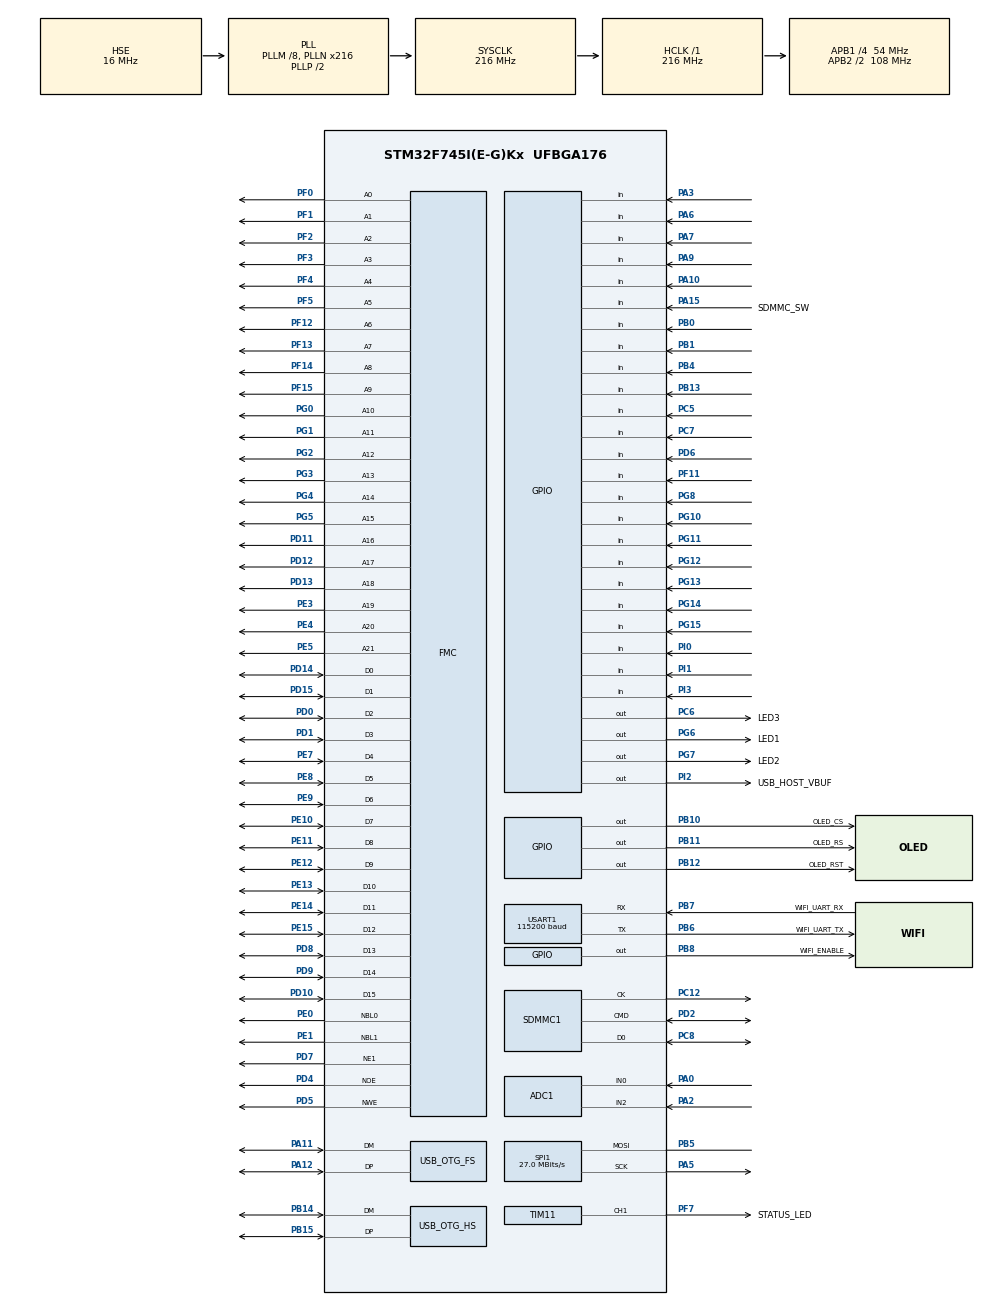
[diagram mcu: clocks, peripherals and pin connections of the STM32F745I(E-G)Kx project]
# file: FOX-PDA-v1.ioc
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ADC1.Channel-0\#ChannelRegularConversion=ADC_CHANNEL_0
ADC1.Channel-1\#ChannelRegularConversion=ADC_CHANNEL_2
ADC1.ClockPrescaler=ADC_CLOCK_SYNC_PCLK_DIV8
ADC1.ContinuousConvMode=ENABLE
ADC1.DMAContinuousRequests=ENABLE
ADC1.NbrOfConversion=2
ADC1.NbrOfConversionFlag=1
ADC1.Rank-0\#ChannelRegularConversion=1
ADC1.Rank-1\#ChannelRegularConversion=2
ADC1.SamplingTime-0\#ChannelRegularConversion=ADC_SAMPLETIME_144CYCLES
ADC1.SamplingTime-1\#ChannelRegularConversion=ADC_SAMPLETIME_144CYCLES
ADC1.master=1
Dma.ADC1.0.Direction=DMA_PERIPH_TO_MEMORY
Dma.ADC1.0.FIFOMode=DMA_FIFOMODE_DISABLE
Dma.ADC1.0.Instance=DMA2_Stream0
Dma.ADC1.0.MemDataAlignment=DMA_MDATAALIGN_WORD
Dma.ADC1.0.MemInc=DMA_MINC_ENABLE
Dma.ADC1.0.Mode=DMA_CIRCULAR
Dma.ADC1.0.PeriphDataAlignment=DMA_PDATAALIGN_WORD
Dma.ADC1.0.PeriphInc=DMA_PINC_DISABLE
Dma.ADC1.0.Priority=DMA_PRIORITY_LOW
Dma.Request0=ADC1
Dma.Request1=SDMMC1_RX
Dma.Request2=SDMMC1_TX
Dma.Request3=SPI1_TX
Dma.SDMMC1_RX.1.Direction=DMA_PERIPH_TO_MEMORY
Dma.SDMMC1_RX.1.FIFOMode=DMA_FIFOMODE_ENABLE
Dma.SDMMC1_RX.1.FIFOThreshold=DMA_FIFO_THRESHOLD_FULL
Dma.SDMMC1_RX.1.Instance=DMA2_Stream3
Dma.SDMMC1_RX.1.MemBurst=DMA_MBURST_INC4
Dma.SDMMC1_RX.1.MemDataAlignment=DMA_MDATAALIGN_WORD
Dma.SDMMC1_RX.1.MemInc=DMA_MINC_ENABLE
Dma.SDMMC1_RX.1.Mode=DMA_PFCTRL
Dma.SDMMC1_RX.1.PeriphBurst=DMA_PBURST_INC4
Dma.SDMMC1_RX.1.PeriphDataAlignment=DMA_PDATAALIGN_WORD
Dma.SDMMC1_RX.1.PeriphInc=DMA_PINC_DISABLE
Dma.SDMMC1_RX.1.Priority=DMA_PRIORITY_LOW
Dma.SDMMC1_TX.2.Direction=DMA_MEMORY_TO_PERIPH
Dma.SDMMC1_TX.2.FIFOMode=DMA_FIFOMODE_ENABLE
Dma.SDMMC1_TX.2.FIFOThreshold=DMA_FIFO_THRESHOLD_FULL
Dma.SDMMC1_TX.2.Instance=DMA2_Stream6
Dma.SDMMC1_TX.2.MemBurst=DMA_MBURST_INC4
Dma.SDMMC1_TX.2.MemDataAlignment=DMA_MDATAALIGN_WORD
Dma.SDMMC1_TX.2.MemInc=DMA_MINC_ENABLE
Dma.SDMMC1_TX.2.Mode=DMA_PFCTRL
Dma.SDMMC1_TX.2.PeriphBurst=DMA_PBURST_INC4
Dma.SDMMC1_TX.2.PeriphDataAlignment=DMA_PDATAALIGN_WORD
Dma.SDMMC1_TX.2.PeriphInc=DMA_PINC_DISABLE
Dma.SDMMC1_TX.2.Priority=DMA_PRIORITY_LOW
Dma.SPI1_TX.3.Direction=DMA_MEMORY_TO_PERIPH
Dma.SPI1_TX.3.FIFOMode=DMA_FIFOMODE_DISABLE
Dma.SPI1_TX.3.Instance=DMA2_Stream5
Dma.SPI1_TX.3.MemDataAlignment=DMA_MDATAALIGN_BYTE
Dma.SPI1_TX.3.MemInc=DMA_MINC_DISABLE
Dma.SPI1_TX.3.Mode=DMA_NORMAL
Dma.SPI1_TX.3.PeriphDataAlignment=DMA_PDATAALIGN_BYTE
Dma.SPI1_TX.3.PeriphInc=DMA_PINC_DISABLE
Dma.SPI1_TX.3.Priority=DMA_PRIORITY_VERY_HIGH
FATFS.BSP.number=1
FATFS.USE_DMA_CODE_SD=0
FATFS._FS_NOFSINFO=0
FATFS._MAX_SS=4096
FATFS._MIN_SS=512
FATFS._MULTI_PARTITION=0
FATFS._USE_LFN=1
FATFS0.BSP.STBoard=false
FATFS0.BSP.api=Unknown
FATFS0.BSP.instance=PA15
FATFS0.BSP.ip=GPIO
FATFS0.BSP.mode=Input
FATFS0.BSP.name=Detect_SDIO
FATFS0.BSP.solution=PA15
FMC.AddressSetupTime1=5
FMC.BusTurnAroundDuration1=1
FMC.DataSetupTime1=8
FMC.WriteOperation1=FMC_WRITE_OPERATION_ENABLE
Mcu.Family=STM32F7
Mcu.Name=STM32F745I(E-G)Kx
Mcu.Package=UFBGA176
NVIC.DMA2_Stream0_IRQn=true\:0\:0\:false\:false\:true\:false\:true\:true
NVIC.DMA2_Stream3_IRQn=true\:0\:0\:false\:false\:true\:false\:true\:true
NVIC.DMA2_Stream5_IRQn=true\:0\:0\:false\:false\:true\:false\:true\:true
NVIC.DMA2_Stream6_IRQn=true\:0\:0\:false\:false\:true\:false\:true\:true
NVIC.OTG_FS_IRQn=true\:0\:0\:false\:false\:true\:false\:true\:true
NVIC.OTG_HS_IRQn=true\:0\:0\:false\:false\:true\:false\:true\:true
NVIC.PriorityGroup=NVIC_PRIORITYGROUP_4
NVIC.SPI1_IRQn=true\:0\:0\:false\:false\:true\:true\:true\:true
PA0/WKUP.Signal=ADCx_IN0
PA10.Signal=GPIO_Input
PA11.Mode=Host_Only
PA11.Signal=USB_OTG_FS_DM
PA12.Mode=Host_Only
PA12.Signal=USB_OTG_FS_DP
PA13.Mode=Trace_Asynchronous_SW
PA13.Signal=SYS_JTMS-SWDIO
PA14.Mode=Trace_Asynchronous_SW
PA14.Signal=SYS_JTCK-SWCLK
PA15.GPIO_Label=SDMMC_SW
PA15.Signal=GPIO_Input
PA2.Signal=ADCx_IN2
PA3.Signal=GPIO_Input
PA5.GPIO_Speed=GPIO_SPEED_FREQ_HIGH
PA5.Mode=Simplex_Bidirectional_Master
PA5.Signal=SPI1_SCK
PA6.Signal=GPIO_Input
PA7.Signal=GPIO_Input
PA9.Signal=GPIO_Input
PB0.Signal=GPIO_Input
PB1.Signal=GPIO_Input
PB10.GPIO_Label=OLED_CS
PB10.GPIO_Speed=GPIO_SPEED_FREQ_MEDIUM
PB10.PinState=GPIO_PIN_RESET
PB10.Signal=GPIO_Output
PB11.GPIO_Label=OLED_RS
PB11.GPIO_Speed=GPIO_SPEED_FREQ_MEDIUM
PB11.PinState=GPIO_PIN_RESET
PB11.Signal=GPIO_Output
PB12.GPIO_Label=OLED_RST
PB12.GPIO_Speed=GPIO_SPEED_FREQ_MEDIUM
PB12.PinState=GPIO_PIN_RESET
PB12.Signal=GPIO_Output
PB13.Signal=GPIO_Input
PB14.Mode=Device_Only_FS
PB14.Signal=USB_OTG_HS_DM
PB15.Mode=Device_Only_FS
PB15.Signal=USB_OTG_HS_DP
PB3.Mode=Trace_Asynchronous_SW
PB3.Signal=SYS_JTDO-SWO
PB4.Signal=GPIO_Input
PB5.GPIO_Speed=GPIO_SPEED_FREQ_HIGH
PB5.Mode=Simplex_Bidirectional_Master
PB5.Signal=SPI1_MOSI
PB6.GPIO_Label=WIFI_UART_TX
PB6.Mode=Asynchronous
PB6.Signal=USART1_TX
PB7.GPIO_Label=WIFI_UART_RX
PB7.Mode=Asynchronous
PB7.Signal=USART1_RX
PB8.GPIO_Label=WIFI_ENABLE
PB8.Signal=GPIO_Output
PC10.Signal=SDMMC1_D2
PC11.Signal=SDMMC1_D3
PC12.Mode=SD_1_bit
PC12.Signal=SDMMC1_CK
PC14/OSC32_IN.Mode=LSE-External-Oscillator
PC14/OSC32_IN.Signal=RCC_OSC32_IN
PC15/OSC32_OUT.Mode=LSE-External-Oscillator
PC15/OSC32_OUT.Signal=RCC_OSC32_OUT
PC5.Signal=GPIO_Input
PC6.GPIO_Label=LED3
PC6.Signal=GPIO_Output
PC7.Signal=GPIO_Input
PC8.Mode=SD_1_bit
PC8.Signal=SDMMC1_D0
PC9.Signal=SDMMC1_D1
PD0.Signal=FMC_D2_DA2
PD1.Signal=FMC_D3_DA3
PD10.Signal=FMC_D15_DA15
PD11.Signal=FMC_A16_CLE
PD12.Signal=FMC_A17_ALE
PD13.Signal=FMC_A18
PD14.Signal=FMC_D0_DA0
PD15.Signal=FMC_D1_DA1
PD2.Mode=SD_1_bit
PD2.Signal=SDMMC1_CMD
PD4.Signal=FMC_NOE
PD5.Signal=FMC_NWE
PD6.Signal=GPIO_Input
PD7.Mode=NorPsramChipSelect1_1
PD7.Signal=FMC_NE1
PD8.Signal=FMC_D13_DA13
PD9.Signal=FMC_D14_DA14
PE0.Signal=FMC_NBL0
PE1.Signal=FMC_NBL1
PE10.Signal=FMC_D7_DA7
PE11.Signal=FMC_D8_DA8
PE12.Signal=FMC_D9_DA9
PE13.Signal=FMC_D10_DA10
PE14.Signal=FMC_D11_DA11
PE15.Signal=FMC_D12_DA12
PE3.Signal=FMC_A19
PE4.Signal=FMC_A20
PE5.Signal=FMC_A21
PE7.Signal=FMC_D4_DA4
PE8.Signal=FMC_D5_DA5
PE9.Signal=FMC_D6_DA6
PF0.Signal=FMC_A0
PF1.Signal=FMC_A1
PF11.Signal=GPIO_Input
PF12.Signal=FMC_A6
PF13.Signal=FMC_A7
PF14.Signal=FMC_A8
PF15.Signal=FMC_A9
PF2.Signal=FMC_A2
PF3.Signal=FMC_A3
PF4.Signal=FMC_A4
PF5.Signal=FMC_A5
PF7.GPIO_Label=STATUS_LED
PF7.Signal=S_TIM11_CH1
PG0.Signal=FMC_A10
PG1.Signal=FMC_A11
PG10.Signal=GPIO_Input
PG11.Signal=GPIO_Input
PG12.Signal=GPIO_Input
PG13.Signal=GPIO_Input
PG14.Signal=GPIO_Input
PG15.Signal=GPIO_Input
PG2.Signal=FMC_A12
PG3.Signal=FMC_A13
PG4.Signal=FMC_A14_BA0
PG5.Signal=FMC_A15_BA1
PG6.GPIO_Label=LED1
PG6.Signal=GPIO_Output
PG7.GPIO_Label=LED2
PG7.Signal=GPIO_Output
PG8.Signal=GPIO_Input
PH0/OSC_IN.Mode=HSE-External-Oscillator
PH0/OSC_IN.Signal=RCC_OSC_IN
PH1/OSC_OUT.Mode=HSE-External-Oscillator
PH1/OSC_OUT.Signal=RCC_OSC_OUT
PI0.Signal=GPIO_Input
PI1.Signal=GPIO_Input
PI2.GPIO_Label=USB_HOST_VBUF
PI2.Signal=GPIO_Output
PI3.Signal=GPIO_Input
ProjectManager.HeapSize=0x200
ProjectManager.StackSize=0x400
ProjectManager.TargetToolchain=STM32CubeIDE
RCC.AHBFreq_Value=216000000
RCC.APB1CLKDivider=RCC_HCLK_DIV4
RCC.APB1Freq_Value=54000000
RCC.APB1TimFreq_Value=108000000
RCC.APB2CLKDivider=RCC_HCLK_DIV2
RCC.APB2Freq_Value=108000000
RCC.APB2TimFreq_Value=216000000
RCC.CortexFreq_Value=216000000
RCC.HCLKFreq_Value=216000000
RCC.HSE_VALUE=16000000
RCC.HSI_VALUE=16000000
RCC.PLLI2SN=181
RCC.PLLM=8
RCC.PLLN=216
RCC.PLLQ=9
RCC.PLLSAIN=50
RCC.SDMMCClockSelection=RCC_SDMMC1CLKSOURCE_CLK48
RCC.SYSCLKFreq_VALUE=216000000
RCC.SYSCLKSource=RCC_SYSCLKSOURCE_PLLCLK
RCC.USBFreq_Value=48000000
RCC.VCOOutputFreq_Value=432000000
SDMMC1.ClockBypass=SDMMC_CLOCK_BYPASS_DISABLE
SDMMC1.ClockDiv=4
SDMMC1.HardwareFlowControl=SDMMC_HARDWARE_FLOW_CONTROL_ENABLE
SH.ADCx_IN0.0=ADC1_IN0,IN0
SH.ADCx_IN2.0=ADC1_IN2,IN2
SH.FMC_A0.0=FMC_A0,22b-a1
SH.FMC_A1.0=FMC_A1,22b-a1
SH.FMC_A10.0=FMC_A10,22b-a1
SH.FMC_A11.0=FMC_A11,22b-a1
SH.FMC_A12.0=FMC_A12,22b-a1
SH.FMC_A13.0=FMC_A13,22b-a1
SH.FMC_A14_BA0.0=FMC_A14,22b-a1
SH.FMC_A15_BA1.0=FMC_A15,22b-a1
SH.FMC_A16_CLE.0=FMC_A16,22b-a1
SH.FMC_A17_ALE.0=FMC_A17,22b-a1
SH.FMC_A18.0=FMC_A18,22b-a1
SH.FMC_A19.0=FMC_A19,22b-a1
SH.FMC_A2.0=FMC_A2,22b-a1
SH.FMC_A20.0=FMC_A20,22b-a1
SH.FMC_A21.0=FMC_A21,22b-a1
SH.FMC_A3.0=FMC_A3,22b-a1
SH.FMC_A4.0=FMC_A4,22b-a1
SH.FMC_A5.0=FMC_A5,22b-a1
SH.FMC_A6.0=FMC_A6,22b-a1
SH.FMC_A7.0=FMC_A7,22b-a1
SH.FMC_A8.0=FMC_A8,22b-a1
SH.FMC_A9.0=FMC_A9,22b-a1
SH.FMC_D0_DA0.0=FMC_D0,16b-d1
SH.FMC_D10_DA10.0=FMC_D10,16b-d1
SH.FMC_D11_DA11.0=FMC_D11,16b-d1
SH.FMC_D12_DA12.0=FMC_D12,16b-d1
SH.FMC_D13_DA13.0=FMC_D13,16b-d1
SH.FMC_D14_DA14.0=FMC_D14,16b-d1
SH.FMC_D15_DA15.0=FMC_D15,16b-d1
SH.FMC_D1_DA1.0=FMC_D1,16b-d1
SH.FMC_D2_DA2.0=FMC_D2,16b-d1
SH.FMC_D3_DA3.0=FMC_D3,16b-d1
SH.FMC_D4_DA4.0=FMC_D4,16b-d1
SH.FMC_D5_DA5.0=FMC_D5,16b-d1
SH.FMC_D6_DA6.0=FMC_D6,16b-d1
SH.FMC_D7_DA7.0=FMC_D7,16b-d1
SH.FMC_D8_DA8.0=FMC_D8,16b-d1
SH.FMC_D9_DA9.0=FMC_D9,16b-d1
SH.FMC_NBL0.0=FMC_NBL0,2ByteEnable1
SH.FMC_NBL1.0=FMC_NBL1,2ByteEnable1
SH.FMC_NOE.0=FMC_NOE,Psram1
SH.FMC_NWE.0=FMC_NWE,Psram1
SH.S_TIM11_CH1.0=TIM11_CH1,PWM Generation1 CH1
SPI1.BaudRatePrescaler=SPI_BAUDRATEPRESCALER_4
SPI1.CalculateBaudRate=27.0 MBits/s
SPI1.DataSize=SPI_DATASIZE_8BIT
SPI1.Direction=SPI_DIRECTION_1LINE
SPI1.Mode=SPI_MODE_MASTER
SPI1.VirtualType=VM_MASTER
TIM11.Channel=TIM_CHANNEL_1
USART1.BaudRate=115200
USART1.VirtualMode-Asynchronous=VM_ASYNC
USART1.WordLength=WORDLENGTH_8B
USB_DEVICE.CLASS_NAME_HS=CDC
USB_DEVICE.VirtualMode-CDC_HS=Cdc
USB_DEVICE.VirtualModeHS=Cdc_HS
USB_HOST.BSP.number=1
USB_HOST.USBH_HandleTypeDef-CDC_FS=hUsbHostFS
USB_HOST.VirtualModeFS=Cdc
USB_HOST0.BSP.STBoard=false
USB_HOST0.BSP.api=Unknown
USB_HOST0.BSP.instance=PI2
USB_HOST0.BSP.ip=GPIO
USB_HOST0.BSP.mode=Output
USB_HOST0.BSP.name=Drive_VBUS_FS
USB_HOST0.BSP.solution=PI2
USB_OTG_FS.VirtualMode=Host_Only
USB_OTG_FS.phy_itface=HCD_PHY_EMBEDDED
USB_OTG_HS.VirtualMode-Device_Only_FS=Device_Only_FS
VP_FATFS_VS_SDIO.Mode=SDIO
VP_TIM11_VS_ClockSourceINT.Mode=Enable_Timer
VP_TIM1_VS_ClockSourceINT.Mode=Internal
VP_USB_DEVICE_VS_USB_DEVICE_CDC_HS.Mode=CDC_HS
VP_USB_HOST_VS_USB_HOST_CDC_FS.Mode=CDC_FS
board=custom

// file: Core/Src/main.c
/* USER CODE BEGIN Header */
/**
 ******************************************************************************
 * @file           : main.c
 * @brief          : Main program body
 ******************************************************************************
 * @attention
 *
 * Copyright (c) 2023 STMicroelectronics.
 * All rights reserved.
 *
 * This software is licensed under terms that can be found in the LICENSE file
 * in the root directory of this software component.
 * If no LICENSE file comes with this software, it is provided AS-IS.
 *
 ******************************************************************************
 */
/* USER CODE END Header */
#include "main.h"
#include "fatfs.h"
#include "usb_device.h"
#include "usb_host.h"

/* USER CODE BEGIN Includes */
#include "usbd_cdc_if.h"
#include "string.h"
#include "stm32f7xx_ll_fmc.h"
#include "math.h"

#include "Ffunctions/f_debug.h"
#include "System/System.h"

#include "Drivers/MDT0096AIH.h"
/* USER CODE END Includes */

ADC_HandleTypeDef hadc1;
DMA_HandleTypeDef hdma_adc1;

SD_HandleTypeDef hsd1;
DMA_HandleTypeDef hdma_sdmmc1_rx;
DMA_HandleTypeDef hdma_sdmmc1_tx;

SPI_HandleTypeDef hspi1;
DMA_HandleTypeDef hdma_spi1_tx;

TIM_HandleTypeDef htim1;
TIM_HandleTypeDef htim11;

UART_HandleTypeDef huart1;

SRAM_HandleTypeDef hsram1;

/* USER CODE BEGIN PV */

// system state management
System_t system_state;

MDT0096AIH_t oled;

/* USER CODE END PV */

void SystemClock_Config(void);
static void MX_GPIO_Init(void);
static void MX_DMA_Init(void);
static void MX_SDMMC1_SD_Init(void);
static void MX_USART1_UART_Init(void);
static void MX_TIM1_Init(void);
static void MX_TIM11_Init(void);
static void MX_ADC1_Init(void);
static void MX_FMC_Init(void);
static void MX_SPI1_Init(void);
void MX_USB_HOST_Process(void);

/* USER CODE BEGIN 0 */
uint8_t adc_ready = 0;
uint32_t adc_buffer[2];
uint32_t adc_dma_buffer[2];
void HAL_ADC_ConvCpltCallback(ADC_HandleTypeDef *AdcHandle)
{
	adc_ready = 1;
	memcpy(adc_buffer, adc_dma_buffer, 2 * sizeof(uint32_t));
}

/* USER CODE END 0 */

int main(void)
{

	/* MCU Configuration--------------------------------------------------------*/

	/* Reset of all peripherals, Initializes the Flash interface and the Systick. */
	HAL_Init();

	/* Configure the system clock */
	SystemClock_Config();

	/* Initialize all configured peripherals */
	MX_GPIO_Init();
	MX_DMA_Init();
	MX_SDMMC1_SD_Init();
	MX_FATFS_Init();
	MX_USB_DEVICE_Init();
	MX_USB_HOST_Init();
	MX_USART1_UART_Init();
	MX_TIM1_Init();
	MX_TIM11_Init();
	MX_ADC1_Init();
	MX_FMC_Init();
	MX_SPI1_Init();
	/* USER CODE BEGIN 2 */

	//	// system startup
	//	System_init(&system_state);
	//
	//	// system init terminal log
	//	System_initLog(&system_state);
	//	System_selfTestLog(&system_state);

	HAL_Delay(1000);

	// init display
	MDT0096AIH_Init(&oled, &hspi1,
			OLED_RS_GPIO_Port, OLED_RS_Pin,
			OLED_RST_GPIO_Port, OLED_RST_Pin,
			OLED_CS_GPIO_Port, OLED_CS_Pin);

	uint8_t frame_buffer[38400];// = (uint8_t*)SRAM_ADDRESS;
	uint8_t brightness = 0x00;
	/* USER CODE END 2 */

	/* Infinite loop */
	/* USER CODE BEGIN WHILE */
	while (1)
	{
		brightness += 1;
		memset(frame_buffer, brightness, 38400);
		HAL_SPI_Transmit_DMA(&hspi1, frame_buffer, 38400);
		HAL_Delay(16);
		/* USER CODE END WHILE */
		MX_USB_HOST_Process();
	}
}

void SystemClock_Config(void)
{
	RCC_OscInitTypeDef RCC_OscInitStruct = {0};
	RCC_ClkInitTypeDef RCC_ClkInitStruct = {0};

	/** Configure LSE Drive Capability
	 */
	HAL_PWR_EnableBkUpAccess();

	/** Configure the main internal regulator output voltage
	 */
	__HAL_RCC_PWR_CLK_ENABLE();
	__HAL_PWR_VOLTAGESCALING_CONFIG(PWR_REGULATOR_VOLTAGE_SCALE1);

	/** Initializes the RCC Oscillators according to the specified parameters
	 * in the RCC_OscInitTypeDef structure.
	 */
	RCC_OscInitStruct.OscillatorType = RCC_OSCILLATORTYPE_HSE;
	RCC_OscInitStruct.HSEState = RCC_HSE_ON;
	RCC_OscInitStruct.PLL.PLLState = RCC_PLL_ON;
	RCC_OscInitStruct.PLL.PLLSource = RCC_PLLSOURCE_HSE;
	RCC_OscInitStruct.PLL.PLLM = 8;
	RCC_OscInitStruct.PLL.PLLN = 216;
	RCC_OscInitStruct.PLL.PLLP = RCC_PLLP_DIV2;
	RCC_OscInitStruct.PLL.PLLQ = 9;
	if (HAL_RCC_OscConfig(&RCC_OscInitStruct) != HAL_OK)
	{
		Error_Handler();
	}

	/** Activate the Over-Drive mode
	 */
	if (HAL_PWREx_EnableOverDrive() != HAL_OK)
	{
		Error_Handler();
	}

	/** Initializes the CPU, AHB and APB buses clocks
	 */
	RCC_ClkInitStruct.ClockType = RCC_CLOCKTYPE_HCLK|RCC_CLOCKTYPE_SYSCLK
			|RCC_CLOCKTYPE_PCLK1|RCC_CLOCKTYPE_PCLK2;
	RCC_ClkInitStruct.SYSCLKSource = RCC_SYSCLKSOURCE_PLLCLK;
	RCC_ClkInitStruct.AHBCLKDivider = RCC_SYSCLK_DIV1;
	RCC_ClkInitStruct.APB1CLKDivider = RCC_HCLK_DIV4;
	RCC_ClkInitStruct.APB2CLKDivider = RCC_HCLK_DIV2;

	if (HAL_RCC_ClockConfig(&RCC_ClkInitStruct, FLASH_LATENCY_7) != HAL_OK)
	{
		Error_Handler();
	}
}

static void MX_ADC1_Init(void)
{

	ADC_ChannelConfTypeDef sConfig = {0};

	/** Configure the global features of the ADC (Clock, Resolution, Data Alignment and number of conversion)
	 */
	hadc1.Instance = ADC1;
	hadc1.Init.ClockPrescaler = ADC_CLOCK_SYNC_PCLK_DIV8;
	hadc1.Init.Resolution = ADC_RESOLUTION_12B;
	hadc1.Init.ScanConvMode = ADC_SCAN_ENABLE;
	hadc1.Init.ContinuousConvMode = ENABLE;
	hadc1.Init.DiscontinuousConvMode = DISABLE;
	hadc1.Init.ExternalTrigConvEdge = ADC_EXTERNALTRIGCONVEDGE_NONE;
	hadc1.Init.ExternalTrigConv = ADC_SOFTWARE_START;
	hadc1.Init.DataAlign = ADC_DATAALIGN_RIGHT;
	hadc1.Init.NbrOfConversion = 2;
	hadc1.Init.DMAContinuousRequests = ENABLE;
	hadc1.Init.EOCSelection = ADC_EOC_SINGLE_CONV;
	if (HAL_ADC_Init(&hadc1) != HAL_OK)
	{
		Error_Handler();
	}

	/** Configure for the selected ADC regular channel its corresponding rank in the sequencer and its sample time.
	 */
	sConfig.Channel = ADC_CHANNEL_0;
	sConfig.Rank = ADC_REGULAR_RANK_1;
	sConfig.SamplingTime = ADC_SAMPLETIME_144CYCLES;
	if (HAL_ADC_ConfigChannel(&hadc1, &sConfig) != HAL_OK)
	{
		Error_Handler();
	}

	/** Configure for the selected ADC regular channel its corresponding rank in the sequencer and its sample time.
	 */
	sConfig.Channel = ADC_CHANNEL_2;
	sConfig.Rank = ADC_REGULAR_RANK_2;
	if (HAL_ADC_ConfigChannel(&hadc1, &sConfig) != HAL_OK)
	{
		Error_Handler();
	}

}

static void MX_SDMMC1_SD_Init(void)
{

	hsd1.Instance = SDMMC1;
	hsd1.Init.ClockEdge = SDMMC_CLOCK_EDGE_RISING;
	hsd1.Init.ClockBypass = SDMMC_CLOCK_BYPASS_DISABLE;
	hsd1.Init.ClockPowerSave = SDMMC_CLOCK_POWER_SAVE_DISABLE;
	hsd1.Init.BusWide = SDMMC_BUS_WIDE_1B;
	hsd1.Init.HardwareFlowControl = SDMMC_HARDWARE_FLOW_CONTROL_ENABLE;
	hsd1.Init.ClockDiv = 4;
	/* USER CODE BEGIN SDMMC1_Init 2 */
	HAL_SD_Init(&hsd1);
	/* USER CODE END SDMMC1_Init 2 */

}

static void MX_SPI1_Init(void)
{

	/* SPI1 parameter configuration*/
	hspi1.Instance = SPI1;
	hspi1.Init.Mode = SPI_MODE_MASTER;
	hspi1.Init.Direction = SPI_DIRECTION_1LINE;
	hspi1.Init.DataSize = SPI_DATASIZE_8BIT;
	hspi1.Init.CLKPolarity = SPI_POLARITY_LOW;
	hspi1.Init.CLKPhase = SPI_PHASE_1EDGE;
	hspi1.Init.NSS = SPI_NSS_SOFT;
	hspi1.Init.BaudRatePrescaler = SPI_BAUDRATEPRESCALER_4;
	hspi1.Init.FirstBit = SPI_FIRSTBIT_MSB;
	hspi1.Init.TIMode = SPI_TIMODE_DISABLE;
	hspi1.Init.CRCCalculation = SPI_CRCCALCULATION_DISABLE;
	hspi1.Init.CRCPolynomial = 7;
	hspi1.Init.CRCLength = SPI_CRC_LENGTH_DATASIZE;
	hspi1.Init.NSSPMode = SPI_NSS_PULSE_ENABLE;
	if (HAL_SPI_Init(&hspi1) != HAL_OK)
	{
		Error_Handler();
	}

}

static void MX_TIM1_Init(void)
{

	TIM_ClockConfigTypeDef sClockSourceConfig = {0};
	TIM_MasterConfigTypeDef sMasterConfig = {0};

	htim1.Instance = TIM1;
	htim1.Init.Prescaler = 0;
	htim1.Init.CounterMode = TIM_COUNTERMODE_UP;
	htim1.Init.Period = 65535;
	htim1.Init.ClockDivision = TIM_CLOCKDIVISION_DIV1;
	htim1.Init.RepetitionCounter = 0;
	htim1.Init.AutoReloadPreload = TIM_AUTORELOAD_PRELOAD_DISABLE;
	if (HAL_TIM_Base_Init(&htim1) != HAL_OK)
	{
		Error_Handler();
	}
	sClockSourceConfig.ClockSource = TIM_CLOCKSOURCE_INTERNAL;
	if (HAL_TIM_ConfigClockSource(&htim1, &sClockSourceConfig) != HAL_OK)
	{
		Error_Handler();
	}
	sMasterConfig.MasterOutputTrigger = TIM_TRGO_RESET;
	sMasterConfig.MasterOutputTrigger2 = TIM_TRGO2_RESET;
	sMasterConfig.MasterSlaveMode = TIM_MASTERSLAVEMODE_DISABLE;
	if (HAL_TIMEx_MasterConfigSynchronization(&htim1, &sMasterConfig) != HAL_OK)
	{
		Error_Handler();
	}

}

static void MX_TIM11_Init(void)
{

	TIM_OC_InitTypeDef sConfigOC = {0};

	htim11.Instance = TIM11;
	htim11.Init.Prescaler = 0;
	htim11.Init.CounterMode = TIM_COUNTERMODE_UP;
	htim11.Init.Period = 65535;
	htim11.Init.ClockDivision = TIM_CLOCKDIVISION_DIV1;
	htim11.Init.AutoReloadPreload = TIM_AUTORELOAD_PRELOAD_DISABLE;
	if (HAL_TIM_Base_Init(&htim11) != HAL_OK)
	{
		Error_Handler();
	}
	if (HAL_TIM_PWM_Init(&htim11) != HAL_OK)
	{
		Error_Handler();
	}
	sConfigOC.OCMode = TIM_OCMODE_PWM1;
	sConfigOC.Pulse = 0;
	sConfigOC.OCPolarity = TIM_OCPOLARITY_HIGH;
	sConfigOC.OCFastMode = TIM_OCFAST_DISABLE;
	if (HAL_TIM_PWM_ConfigChannel(&htim11, &sConfigOC, TIM_CHANNEL_1) != HAL_OK)
	{
		Error_Handler();
	}
	HAL_TIM_MspPostInit(&htim11);

}

static void MX_USART1_UART_Init(void)
{

	huart1.Instance = USART1;
	huart1.Init.BaudRate = 115200;
	huart1.Init.WordLength = UART_WORDLENGTH_8B;
	huart1.Init.StopBits = UART_STOPBITS_1;
	huart1.Init.Parity = UART_PARITY_NONE;
	huart1.Init.Mode = UART_MODE_TX_RX;
	huart1.Init.HwFlowCtl = UART_HWCONTROL_NONE;
	huart1.Init.OverSampling = UART_OVERSAMPLING_16;
	huart1.Init.OneBitSampling = UART_ONE_BIT_SAMPLE_DISABLE;
	huart1.AdvancedInit.AdvFeatureInit = UART_ADVFEATURE_NO_INIT;
	if (HAL_UART_Init(&huart1) != HAL_OK)
	{
		Error_Handler();
	}

}

static void MX_DMA_Init(void)
{

	/* DMA controller clock enable */
	__HAL_RCC_DMA2_CLK_ENABLE();

	/* DMA interrupt init */
	/* DMA2_Stream0_IRQn interrupt configuration */
	HAL_NVIC_SetPriority(DMA2_Stream0_IRQn, 0, 0);
	HAL_NVIC_EnableIRQ(DMA2_Stream0_IRQn);
	/* DMA2_Stream3_IRQn interrupt configuration */
	HAL_NVIC_SetPriority(DMA2_Stream3_IRQn, 0, 0);
	HAL_NVIC_EnableIRQ(DMA2_Stream3_IRQn);
	/* DMA2_Stream5_IRQn interrupt configuration */
	HAL_NVIC_SetPriority(DMA2_Stream5_IRQn, 0, 0);
	HAL_NVIC_EnableIRQ(DMA2_Stream5_IRQn);
	/* DMA2_Stream6_IRQn interrupt configuration */
	HAL_NVIC_SetPriority(DMA2_Stream6_IRQn, 0, 0);
	HAL_NVIC_EnableIRQ(DMA2_Stream6_IRQn);

}

/* FMC initialization function */
static void MX_FMC_Init(void)
{

	FMC_NORSRAM_TimingTypeDef Timing = {0};

	/** Perform the SRAM1 memory initialization sequence
	 */
	hsram1.Instance = FMC_NORSRAM_DEVICE;
	hsram1.Extended = FMC_NORSRAM_EXTENDED_DEVICE;
	/* hsram1.Init */
	hsram1.Init.NSBank = FMC_NORSRAM_BANK1;
	hsram1.Init.DataAddressMux = FMC_DATA_ADDRESS_MUX_DISABLE;
	hsram1.Init.MemoryType = FMC_MEMORY_TYPE_PSRAM;
	hsram1.Init.MemoryDataWidth = FMC_NORSRAM_MEM_BUS_WIDTH_16;
	hsram1.Init.BurstAccessMode = FMC_BURST_ACCESS_MODE_DISABLE;
	hsram1.Init.WaitSignalPolarity = FMC_WAIT_SIGNAL_POLARITY_LOW;
	hsram1.Init.WaitSignalActive = FMC_WAIT_TIMING_BEFORE_WS;
	hsram1.Init.WriteOperation = FMC_WRITE_OPERATION_ENABLE;
	hsram1.Init.WaitSignal = FMC_WAIT_SIGNAL_DISABLE;
	hsram1.Init.ExtendedMode = FMC_EXTENDED_MODE_DISABLE;
	hsram1.Init.AsynchronousWait = FMC_ASYNCHRONOUS_WAIT_DISABLE;
	hsram1.Init.WriteBurst = FMC_WRITE_BURST_DISABLE;
	hsram1.Init.ContinuousClock = FMC_CONTINUOUS_CLOCK_SYNC_ONLY;
	hsram1.Init.WriteFifo = FMC_WRITE_FIFO_ENABLE;
	hsram1.Init.PageSize = FMC_PAGE_SIZE_NONE;
	/* Timing */
	Timing.AddressSetupTime = 5;
	Timing.AddressHoldTime = 15;
	Timing.DataSetupTime = 8;
	Timing.BusTurnAroundDuration = 1;
	Timing.CLKDivision = 16;
	Timing.DataLatency = 17;
	Timing.AccessMode = FMC_ACCESS_MODE_A;
	/* ExtTiming */

	if (HAL_SRAM_Init(&hsram1, &Timing, NULL) != HAL_OK)
	{
		Error_Handler( );
	}

}

static void MX_GPIO_Init(void)
{
	GPIO_InitTypeDef GPIO_InitStruct = {0};

	/* GPIO Ports Clock Enable */
	__HAL_RCC_GPIOE_CLK_ENABLE();
	__HAL_RCC_GPIOB_CLK_ENABLE();
	__HAL_RCC_GPIOG_CLK_ENABLE();
	__HAL_RCC_GPIOD_CLK_ENABLE();
	__HAL_RCC_GPIOC_CLK_ENABLE();
	__HAL_RCC_GPIOA_CLK_ENABLE();
	__HAL_RCC_GPIOI_CLK_ENABLE();
	__HAL_RCC_GPIOF_CLK_ENABLE();
	__HAL_RCC_GPIOH_CLK_ENABLE();

	/*Configure GPIO pin Output Level */
	HAL_GPIO_WritePin(GPIOB, WIFI_ENABLE_Pin|OLED_RST_Pin|OLED_CS_Pin|OLED_RS_Pin, GPIO_PIN_RESET);

	/*Configure GPIO pin Output Level */
	HAL_GPIO_WritePin(USB_HOST_VBUF_GPIO_Port, USB_HOST_VBUF_Pin, GPIO_PIN_RESET);

	/*Configure GPIO pin Output Level */
	HAL_GPIO_WritePin(LED3_GPIO_Port, LED3_Pin, GPIO_PIN_RESET);

	/*Configure GPIO pin Output Level */
	HAL_GPIO_WritePin(GPIOG, LED2_Pin|LED1_Pin, GPIO_PIN_RESET);

	/*Configure GPIO pin : WIFI_ENABLE_Pin */
	GPIO_InitStruct.Pin = WIFI_ENABLE_Pin;
	GPIO_InitStruct.Mode = GPIO_MODE_OUTPUT_PP;
	GPIO_InitStruct.Pull = GPIO_NOPULL;
	GPIO_InitStruct.Speed = GPIO_SPEED_FREQ_LOW;
	HAL_GPIO_Init(WIFI_ENABLE_GPIO_Port, &GPIO_InitStruct);

	/*Configure GPIO pins : PG14 PG13 PG15 PG12
                           PG11 PG10 PG8 */
	GPIO_InitStruct.Pin = GPIO_PIN_14|GPIO_PIN_13|GPIO_PIN_15|GPIO_PIN_12
			|GPIO_PIN_11|GPIO_PIN_10|GPIO_PIN_8;
	GPIO_InitStruct.Mode = GPIO_MODE_INPUT;
	GPIO_InitStruct.Pull = GPIO_NOPULL;
	HAL_GPIO_Init(GPIOG, &GPIO_InitStruct);

	/*Configure GPIO pins : PB4 PB13 PB1 PB0 */
	GPIO_InitStruct.Pin = GPIO_PIN_4|GPIO_PIN_13|GPIO_PIN_1|GPIO_PIN_0;
	GPIO_InitStruct.Mode = GPIO_MODE_INPUT;
	GPIO_InitStruct.Pull = GPIO_NOPULL;
	HAL_GPIO_Init(GPIOB, &GPIO_InitStruct);

	/*Configure GPIO pins : SDMMC_SW_Pin PA10 PA9 PA6
                           PA3 PA7 */
	GPIO_InitStruct.Pin = SDMMC_SW_Pin|GPIO_PIN_10|GPIO_PIN_9|GPIO_PIN_6
			|GPIO_PIN_3|GPIO_PIN_7;
	GPIO_InitStruct.Mode = GPIO_MODE_INPUT;
	GPIO_InitStruct.Pull = GPIO_NOPULL;
	HAL_GPIO_Init(GPIOA, &GPIO_InitStruct);

	/*Configure GPIO pin : PD6 */
	GPIO_InitStruct.Pin = GPIO_PIN_6;
	GPIO_InitStruct.Mode = GPIO_MODE_INPUT;
	GPIO_InitStruct.Pull = GPIO_NOPULL;
	HAL_GPIO_Init(GPIOD, &GPIO_InitStruct);

	/*Configure GPIO pins : PI3 PI1 PI0 */
	GPIO_InitStruct.Pin = GPIO_PIN_3|GPIO_PIN_1|GPIO_PIN_0;
	GPIO_InitStruct.Mode = GPIO_MODE_INPUT;
	GPIO_InitStruct.Pull = GPIO_NOPULL;
	HAL_GPIO_Init(GPIOI, &GPIO_InitStruct);

	/*Configure GPIO pin : USB_HOST_VBUF_Pin */
	GPIO_InitStruct.Pin = USB_HOST_VBUF_Pin;
	GPIO_InitStruct.Mode = GPIO_MODE_OUTPUT_PP;
	GPIO_InitStruct.Pull = GPIO_NOPULL;
	GPIO_InitStruct.Speed = GPIO_SPEED_FREQ_LOW;
	HAL_GPIO_Init(USB_HOST_VBUF_GPIO_Port, &GPIO_InitStruct);

	/*Configure GPIO pins : PC7 PC5 */
	GPIO_InitStruct.Pin = GPIO_PIN_7|GPIO_PIN_5;
	GPIO_InitStruct.Mode = GPIO_MODE_INPUT;
	GPIO_InitStruct.Pull = GPIO_NOPULL;
	HAL_GPIO_Init(GPIOC, &GPIO_InitStruct);

	/*Configure GPIO pin : LED3_Pin */
	GPIO_InitStruct.Pin = LED3_Pin;
	GPIO_InitStruct.Mode = GPIO_MODE_OUTPUT_PP;
	GPIO_InitStruct.Pull = GPIO_NOPULL;
	GPIO_InitStruct.Speed = GPIO_SPEED_FREQ_LOW;
	HAL_GPIO_Init(LED3_GPIO_Port, &GPIO_InitStruct);

	/*Configure GPIO pins : LED2_Pin LED1_Pin */
	GPIO_InitStruct.Pin = LED2_Pin|LED1_Pin;
	GPIO_InitStruct.Mode = GPIO_MODE_OUTPUT_PP;
	GPIO_InitStruct.Pull = GPIO_NOPULL;
	GPIO_InitStruct.Speed = GPIO_SPEED_FREQ_LOW;
	HAL_GPIO_Init(GPIOG, &GPIO_InitStruct);

	/*Configure GPIO pins : OLED_RST_Pin OLED_CS_Pin OLED_RS_Pin */
	GPIO_InitStruct.Pin = OLED_RST_Pin|OLED_CS_Pin|OLED_RS_Pin;
	GPIO_InitStruct.Mode = GPIO_MODE_OUTPUT_PP;
	GPIO_InitStruct.Pull = GPIO_NOPULL;
	GPIO_InitStruct.Speed = GPIO_SPEED_FREQ_MEDIUM;
	HAL_GPIO_Init(GPIOB, &GPIO_InitStruct);

	/*Configure GPIO pin : PF11 */
	GPIO_InitStruct.Pin = GPIO_PIN_11;
	GPIO_InitStruct.Mode = GPIO_MODE_INPUT;
	GPIO_InitStruct.Pull = GPIO_NOPULL;
	HAL_GPIO_Init(GPIOF, &GPIO_InitStruct);

}

void Error_Handler(void)
{
	/* USER CODE BEGIN Error_Handler_Debug */
	/* User can add his own implementation to report the HAL error return state */
	__disable_irq();

	// reset pins
	HAL_GPIO_WritePin(LED1_GPIO_Port, LED1_Pin, GPIO_PIN_RESET);
	HAL_GPIO_WritePin(LED2_GPIO_Port, LED2_Pin, GPIO_PIN_RESET);
	HAL_GPIO_WritePin(LED3_GPIO_Port, LED3_Pin, GPIO_PIN_RESET);

	// blink error code
	while (1)
	{
		switch(system_state.error)
		{
		case SYS_ERROR_SRAM_FAIL:
			HAL_GPIO_TogglePin(LED1_GPIO_Port, LED1_Pin);
			//	HAL_GPIO_TogglePin(LED2_GPIO_Port, LED2_Pin);
			//	HAL_GPIO_TogglePin(LED3_GPIO_Port, LED3_Pin);
			break;

		case SYS_ERROR_SDIO_FAIL:
			//	HAL_GPIO_TogglePin(LED1_GPIO_Port, LED1_Pin);
			HAL_GPIO_TogglePin(LED2_GPIO_Port, LED2_Pin);
			//	HAL_GPIO_TogglePin(LED3_GPIO_Port, LED3_Pin);
			break;

		case SYS_ERROR_WIFI_FAIL:
			HAL_GPIO_TogglePin(LED1_GPIO_Port, LED1_Pin);
			HAL_GPIO_TogglePin(LED2_GPIO_Port, LED2_Pin);
			//	HAL_GPIO_TogglePin(LED3_GPIO_Port, LED3_Pin);
			break;

		default:
			break;
		}

		// loop delay
		for(volatile uint32_t t=0; t<2000000; t++);
	}
	/* USER CODE END Error_Handler_Debug */
}
